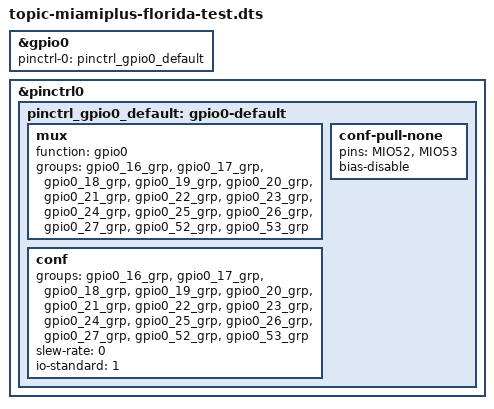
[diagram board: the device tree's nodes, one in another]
/dts-v1/;
/include/ "topic-miami.dtsi"
/include/ "topic-miamiplus.dtsi"
/include/ "topic-miami-florida-test.dtsi"

/* The test board doesn't have ethernet, mux these pins as GPIO instead */
&gpio0 {
	pinctrl-names = "default";
	pinctrl-0 = <&pinctrl_gpio0_default>;
};

&pinctrl0 {
	pinctrl_gpio0_default: gpio0-default {
		mux {
			function = "gpio0";
			groups =
				"gpio0_16_grp",	"gpio0_17_grp",	"gpio0_18_grp",
				"gpio0_19_grp",	"gpio0_20_grp",	"gpio0_21_grp",
				"gpio0_22_grp",	"gpio0_23_grp",	"gpio0_24_grp",
				"gpio0_25_grp",	"gpio0_26_grp",	"gpio0_27_grp",
				"gpio0_52_grp", "gpio0_53_grp";
		};

		conf {
			groups =
				"gpio0_16_grp",	"gpio0_17_grp",	"gpio0_18_grp",
				"gpio0_19_grp",	"gpio0_20_grp",	"gpio0_21_grp",
				"gpio0_22_grp",	"gpio0_23_grp",	"gpio0_24_grp",
				"gpio0_25_grp",	"gpio0_26_grp",	"gpio0_27_grp",
				"gpio0_52_grp", "gpio0_53_grp";
			slew-rate = <0>;
			io-standard = <1>;
		};

		conf-pull-none {
			pins = "MIO52", "MIO53";
			bias-disable;
		};
	};
};
